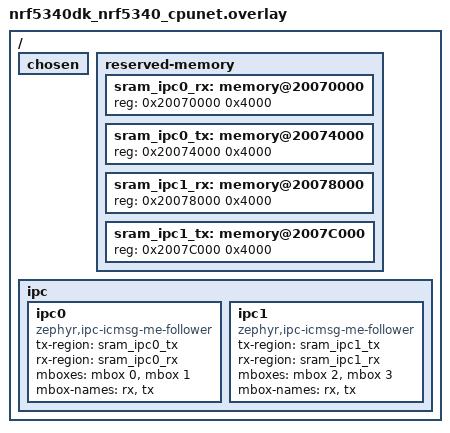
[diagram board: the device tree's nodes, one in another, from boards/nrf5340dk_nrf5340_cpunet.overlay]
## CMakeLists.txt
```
#
# Copyright (c) 2022 Nordic Semiconductor ASA
#
# SPDX-License-Identifier: Apache-2.0
#

cmake_minimum_required(VERSION 3.20.0)

find_package(Zephyr REQUIRED HINTS $ENV{ZEPHYR_BASE})
project(ipc_service_remote)

target_sources(app PRIVATE src/main.c)
```

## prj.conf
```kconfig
CONFIG_PRINTK=y
CONFIG_LOG_PRINTK=n

CONFIG_IPC_SERVICE=y
CONFIG_MBOX=y

CONFIG_LOG=y
CONFIG_IPC_SERVICE_LOG_LEVEL_INF=y
```

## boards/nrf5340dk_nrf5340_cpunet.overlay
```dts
/*
 * Copyright (c) 2022 Nordic Semiconductor ASA
 *
 * SPDX-License-Identifier: Apache-2.0
 */

/ {
	chosen {
		/delete-property/ zephyr,ipc_shm;
	};

	reserved-memory {
		/delete-node/ memory@20070000;

		sram_ipc0_rx: memory@20070000 {
			reg = <0x20070000 0x4000>;
		};

		sram_ipc0_tx: memory@20074000 {
			reg = <0x20074000 0x4000>;
		};

		sram_ipc1_rx: memory@20078000 {
			reg = <0x20078000 0x4000>;
		};

		sram_ipc1_tx: memory@2007C000 {
			reg = <0x2007C000 0x4000>;
		};
	};

	ipc {
		/delete-node/ ipc0;

		ipc0: ipc0 {
			compatible = "zephyr,ipc-icmsg-me-follower";
			tx-region = <&sram_ipc0_tx>;
			rx-region = <&sram_ipc0_rx>;
			mboxes = <&mbox 0>, <&mbox 1>;
			mbox-names = "rx", "tx";
			status = "okay";
		};

		ipc1: ipc1 {
			compatible = "zephyr,ipc-icmsg-me-follower";
			tx-region = <&sram_ipc1_tx>;
			rx-region = <&sram_ipc1_rx>;
			mboxes = <&mbox 2>, <&mbox 3>;
			mbox-names = "rx", "tx";
			status = "okay";
		};
	};
};
```

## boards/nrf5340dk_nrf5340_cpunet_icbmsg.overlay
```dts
/*
 * Copyright (c) 2023 Nordic Semiconductor ASA
 *
 * SPDX-License-Identifier: Apache-2.0
 */

/ {
	chosen {
		/delete-property/ zephyr,ipc_shm;
	};

	reserved-memory {
		/delete-node/ memory@20070000;

		sram_ipc0_rx: memory@20070000 {
			reg = <0x20070000 0x4000>;
		};

		sram_ipc0_tx: memory@20074000 {
			reg = <0x20074000 0x4000>;
		};

		sram_ipc1_rx: memory@20078000 {
			reg = <0x20078000 0x4000>;
		};

		sram_ipc1_tx: memory@2007C000 {
			reg = <0x2007C000 0x4000>;
		};
	};

	ipc {
		/delete-node/ ipc0;

		ipc0: ipc0 {
			compatible = "zephyr,ipc-icbmsg";
			tx-region = <&sram_ipc0_tx>;
			rx-region = <&sram_ipc0_rx>;
			tx-blocks = <24>;
			rx-blocks = <16>;
			mboxes = <&mbox 0>, <&mbox 1>;
			mbox-names = "rx", "tx";
			status = "okay";
		};

		ipc1: ipc1 {
			compatible = "zephyr,ipc-icbmsg";
			tx-region = <&sram_ipc1_tx>;
			rx-region = <&sram_ipc1_rx>;
			tx-blocks = <48>;
			rx-blocks = <32>;
			mboxes = <&mbox 2>, <&mbox 3>;
			mbox-names = "rx", "tx";
			status = "okay";
		};
	};
};
```

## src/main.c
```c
/*
 * Copyright (c) 2022 Nordic Semiconductor ASA
 *
 * SPDX-License-Identifier: Apache-2.0
 */

#include <zephyr/kernel.h>
#include <zephyr/device.h>

#include <zephyr/ipc/ipc_service.h>

#define STACKSIZE	(1024)
#define PRIORITY	K_PRIO_PREEMPT(2)

K_THREAD_STACK_DEFINE(ipc0A_stack, STACKSIZE);
K_THREAD_STACK_DEFINE(ipc0B_stack, STACKSIZE);
K_THREAD_STACK_DEFINE(ipc1_stack, STACKSIZE);

static volatile uint8_t ipc0A_received_data;
static volatile uint8_t ipc0B_received_data;
static volatile uint8_t ipc1_received_data;

static K_SEM_DEFINE(ipc0A_bound_sem, 0, 1);
static K_SEM_DEFINE(ipc0B_bound_sem, 0, 1);
static K_SEM_DEFINE(ipc1_bound_sem, 0, 1);

static K_SEM_DEFINE(ipc0A_data_sem, 0, 1);
static K_SEM_DEFINE(ipc0B_data_sem, 0, 1);
static K_SEM_DEFINE(ipc1_data_sem, 0, 1);

/*
 * ==> THREAD 0A (IPC instance 0 - endpoint A) <==
 */

static void ipc0A_ept_bound(void *priv)
{
	k_sem_give(&ipc0A_bound_sem);
}

static void ipc0A_ept_recv(const void *data, size_t len, void *priv)
{
	ipc0A_received_data = *((uint8_t *) data);

	k_sem_give(&ipc0A_data_sem);
}

static struct ipc_ept_cfg ipc0A_ept_cfg = {
	.name = "ipc0A",
	.cb = {
		.bound    = ipc0A_ept_bound,
		.received = ipc0A_ept_recv,
	},
};

static void ipc0A_entry(void *dummy0, void *dummy1, void *dummy2)
{
	ARG_UNUSED(dummy0);
	ARG_UNUSED(dummy1);
	ARG_UNUSED(dummy2);

	const struct device *ipc0_instance;
	unsigned char message = 0;
	struct ipc_ept ipc0A_ept;
	int ret;

	printk("IPC-service REMOTE [INST 0 - ENDP A] demo started\n");

	ipc0_instance = DEVICE_DT_GET(DT_NODELABEL(ipc0));

	ret = ipc_service_open_instance(ipc0_instance);
	if (ret < 0 && ret != -EALREADY) {
		printk("ipc_service_open_instance() failure\n");
		return;
	}

	ret = ipc_service_register_endpoint(ipc0_instance, &ipc0A_ept, &ipc0A_ept_cfg);
	if (ret < 0) {
		printf("ipc_service_register_endpoint() failure\n");
		return;
	}

	k_sem_take(&ipc0A_bound_sem, K_FOREVER);

	while (message < 99) {
		k_sem_take(&ipc0A_data_sem, K_FOREVER);
		message = ipc0A_received_data;

		printk("REMOTE [0A]: %d\n", message);

		message++;

		ret = ipc_service_send(&ipc0A_ept, &message, sizeof(message));
		if (ret < 0) {
			printk("send_message(%d) failed with ret %d\n", message, ret);
			break;
		}
	}

	printk("IPC-service REMOTE [INST 0 - ENDP A] demo ended.\n");
}
K_THREAD_DEFINE(ipc0A_thread_id, STACKSIZE, ipc0A_entry, NULL, NULL, NULL, PRIORITY, 0, 0);

/*
 * ==> THREAD 0B (IPC instance 0 - endpoint B) <==
 */

static void ipc0B_ept_bound(void *priv)
{
	k_sem_give(&ipc0B_bound_sem);
}

static void ipc0B_ept_recv(const void *data, size_t len, void *priv)
{
	ipc0B_received_data = *((uint8_t *) data);

	k_sem_give(&ipc0B_data_sem);
}

static struct ipc_ept_cfg ipc0B_ept_cfg = {
	.name = "ipc0B",
	.cb = {
		.bound    = ipc0B_ept_bound,
		.received = ipc0B_ept_recv,
	},
};

static void ipc0B_entry(void *dummy0, void *dummy1, void *dummy2)
{
	ARG_UNUSED(dummy0);
	ARG_UNUSED(dummy1);
	ARG_UNUSED(dummy2);

	const struct device *ipc0_instance;
	unsigned char message = 0;
	struct ipc_ept ipc0B_ept;
	int ret;

	printk("IPC-service REMOTE [INST 0 - ENDP B] demo started\n");

	ipc0_instance = DEVICE_DT_GET(DT_NODELABEL(ipc0));

	ret = ipc_service_open_instance(ipc0_instance);
	if (ret < 0 && ret != -EALREADY) {
		printk("ipc_service_open_instance() failure\n");
		return;
	}

	/*
	 * Wait 1 sec to give the opportunity to the PRIMARY core to register
	 * the endpoint first
	 */

	k_sleep(K_MSEC(1000));

	ret = ipc_service_register_endpoint(ipc0_instance, &ipc0B_ept, &ipc0B_ept_cfg);
	if (ret < 0) {
		printf("ipc_service_register_endpoint() failure\n");
		return;
	}

	k_sem_take(&ipc0B_bound_sem, K_FOREVER);

	while (message < 99) {
		k_sem_take(&ipc0B_data_sem, K_FOREVER);
		message = ipc0B_received_data;

		printk("REMOTE [0B]: %d\n", message);

		message++;

		ret = ipc_service_send(&ipc0B_ept, &message, sizeof(message));
		if (ret < 0) {
			printk("send_message(%d) failed with ret %d\n", message, ret);
			break;
		}
	}

	printk("IPC-service REMOTE [INST 0 - ENDP B] demo ended.\n");
}
K_THREAD_DEFINE(ipc0B_thread_id, STACKSIZE, ipc0B_entry, NULL, NULL, NULL, PRIORITY, 0, 0);

/*
 * ==> THREAD 1 (IPC instance 1) <==
 *
 */

static void ipc1_ept_bound(void *priv)
{
	k_sem_give(&ipc1_bound_sem);
}

static void ipc1_ept_recv(const void *data, size_t len, void *priv)
{
	ipc1_received_data = *((uint8_t *) data);

	k_sem_give(&ipc1_data_sem);
}

static struct ipc_ept_cfg ipc1_ept_cfg = {
	.name = "ipc1",
	.cb = {
		.bound    = ipc1_ept_bound,
		.received = ipc1_ept_recv,
	},
};

static void ipc1_entry(void *dummy0, void *dummy1, void *dummy2)
{
	ARG_UNUSED(dummy0);
	ARG_UNUSED(dummy1);
	ARG_UNUSED(dummy2);

	const struct device *ipc1_instance;
	unsigned char message = 0;
	struct ipc_ept ipc1_ept;
	int ret;

	printk("IPC-service REMOTE [INST 1] demo started\n");

	ipc1_instance = DEVICE_DT_GET(DT_NODELABEL(ipc1));

	ret = ipc_service_open_instance(ipc1_instance);
	if (ret < 0 && ret != -EALREADY) {
		printk("ipc_service_open_instance() failure\n");
		return;
	}

	ret = ipc_service_register_endpoint(ipc1_instance, &ipc1_ept, &ipc1_ept_cfg);
	if (ret < 0) {
		printf("ipc_service_register_endpoint() failure\n");
		return;
	}

	k_sem_take(&ipc1_bound_sem, K_FOREVER);

	while (message < 99) {
		k_sem_take(&ipc1_data_sem, K_FOREVER);
		message = ipc1_received_data;

		printk("REMOTE [1]: %d\n", message);

		message++;

		ret = ipc_service_send(&ipc1_ept, &message, sizeof(message));
		if (ret < 0) {
			printk("send_message(%d) failed with ret %d\n", message, ret);
			break;
		}
	}

	printk("IPC-service REMOTE [INST 1] demo ended.\n");
}
K_THREAD_DEFINE(ipc1_thread_id, STACKSIZE, ipc1_entry, NULL, NULL, NULL, PRIORITY, 0, 0);
```
